# N32MC47x_DP47x register map
Vendor: Nsingtech Ltd.; File version: 1.0
Registers are 32-bit, read-write, reset 0x0 unless marked. A register's access mark holds for its fields unless they carry their own. Offsets are from the block's base; [hi:lo] are bit positions; {n}, {i} and the like mark numbered series; 'fields as' and 'values as' point back to an identical list.

## SHRTIM_Common — Super high resolution timer: Common functions
Base 0x40030380
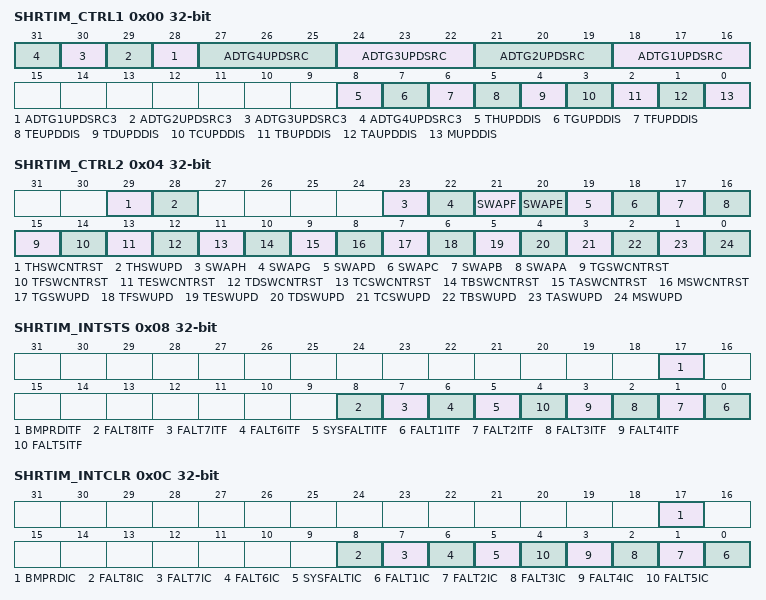
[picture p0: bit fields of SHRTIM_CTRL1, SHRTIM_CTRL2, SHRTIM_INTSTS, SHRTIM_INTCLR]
0x00 SHRTIM_CTRL1
  [n+27] ADTG{n}UPDSRC3 (n=1..4), [3n+15:3n+13] ADTG{n}UPDSRC (n=1..4), [8] THUPDDIS, [7] TGUPDDIS, [6] TFUPDDIS, [5] TEUPDDIS, [4] TDUPDDIS, [3] TCUPDDIS, [2] TBUPDDIS, [1] TAUPDDIS, [0] MUPDDIS
0x04 SHRTIM_CTRL2
  [29] THSWCNTRST, [28] THSWUPD, [23] SWAPH, [22] SWAPG, [21] SWAPF, [20] SWAPE, [19] SWAPD, [18] SWAPC, [17] SWAPB, [16] SWAPA, [15] TGSWCNTRST, [14] TFSWCNTRST, [13] TESWCNTRST, [12] TDSWCNTRST, [11] TCSWCNTRST, [10] TBSWCNTRST, [9] TASWCNTRST, [8] MSWCNTRST, [7] TGSWUPD, [6] TFSWUPD, [5] TESWUPD, [4] TDSWUPD, [3] TCSWUPD, [2] TBSWUPD, [1] TASWUPD, [0] MSWUPD
0x08 SHRTIM_INTSTS ro
  [17] BMPRDITF, [8] FALT8ITF, [7] FALT7ITF, [6] FALT6ITF, [5] SYSFALTITF, [n-1] FALT{n}ITF (n=1..5)
0x0C SHRTIM_INTCLR wo
  [17] BMPRDIC, [8] FALT8IC, [7] FALT7IC, [6] FALT6IC, [5] SYSFALTIC, [n-1] FALT{n}IC (n=1..5)
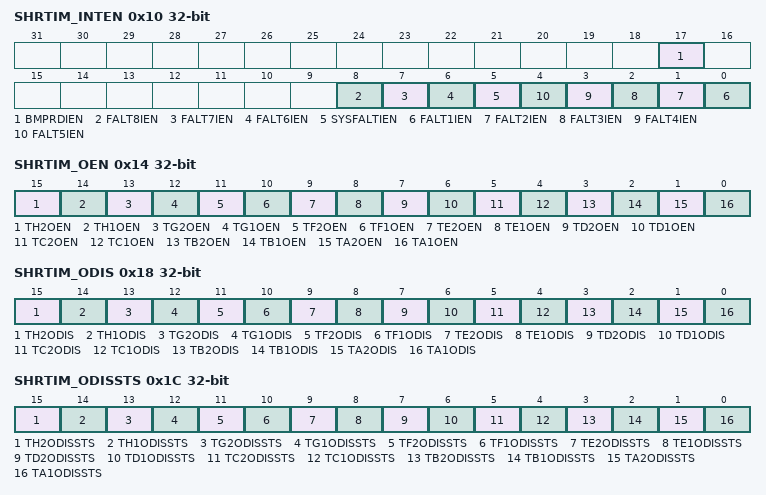
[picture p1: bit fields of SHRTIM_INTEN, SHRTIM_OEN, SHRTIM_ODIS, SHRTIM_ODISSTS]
0x10 SHRTIM_INTEN
  [17] BMPRDIEN, [8] FALT8IEN, [7] FALT7IEN, [6] FALT6IEN, [5] SYSFALTIEN, [n-1] FALT{n}IEN (n=1..5)
0x14 SHRTIM_OEN
  [15] TH2OEN, [14] TH1OEN, [13] TG2OEN, [12] TG1OEN, [11] TF2OEN, [10] TF1OEN, [9] TE2OEN, [8] TE1OEN, [7] TD2OEN, [6] TD1OEN, [5] TC2OEN, [4] TC1OEN, [3] TB2OEN, [2] TB1OEN, [1] TA2OEN, [0] TA1OEN
0x18 SHRTIM_ODIS wo
  [15] TH2ODIS, [14] TH1ODIS, [13] TG2ODIS, [12] TG1ODIS, [11] TF2ODIS, [10] TF1ODIS, [9] TE2ODIS, [8] TE1ODIS, [7] TD2ODIS, [6] TD1ODIS, [5] TC2ODIS, [4] TC1ODIS, [3] TB2ODIS, [2] TB1ODIS, [1] TA2ODIS, [0] TA1ODIS
0x1C SHRTIM_ODISSTS ro
  [15] TH2ODISSTS, [14] TH1ODISSTS, [13] TG2ODISSTS, [12] TG1ODISSTS, [11] TF2ODISSTS, [10] TF1ODISSTS, [9] TE2ODISSTS, [8] TE1ODISSTS, [7] TD2ODISSTS, [6] TD1ODISSTS, [5] TC2ODISSTS, [4] TC1ODISSTS, [3] TB2ODISSTS, [2] TB1ODISSTS, [1] TA2ODISSTS, [0] TA1ODISSTS
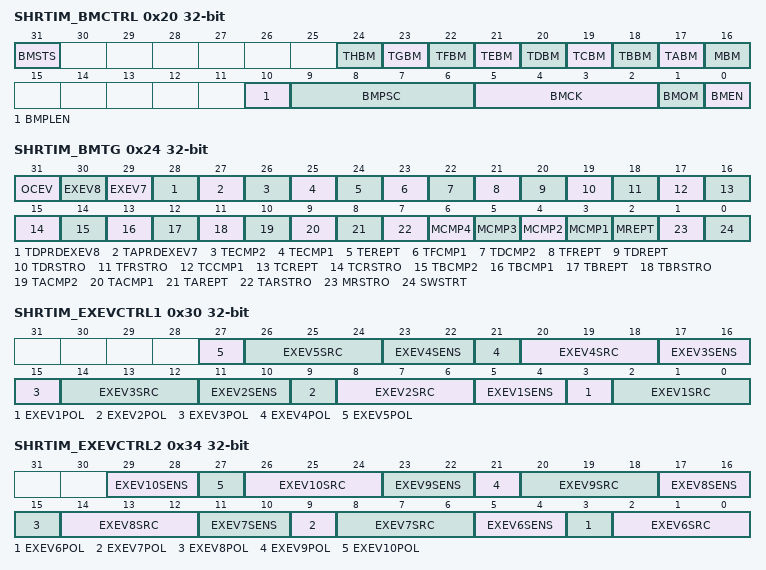
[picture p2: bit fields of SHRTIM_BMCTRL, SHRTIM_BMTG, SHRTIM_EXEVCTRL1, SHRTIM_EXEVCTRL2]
0x20 SHRTIM_BMCTRL
  [31] BMSTS, [24] THBM, [23] TGBM, [22] TFBM, [21] TEBM, [20] TDBM, [19] TCBM, [18] TBBM, [17] TABM, [16] MBM, [10] BMPLEN, [9:6] BMPSC, [5:2] BMCK, [1] BMOM, [0] BMEN
0x24 SHRTIM_BMTG
  [31] OCEV, [30] EXEV8, [29] EXEV7, [28] TDPRDEXEV8, [27] TAPRDEXEV7, [26] TECMP2, [25] TECMP1, [24] TEREPT, [23] TFCMP1, [22] TDCMP2, [21] TFREPT, [20] TDREPT, [19] TDRSTRO, [18] TFRSTRO, [17] TCCMP1, [16] TCREPT, [15] TCRSTRO, [14] TBCMP2, [13] TBCMP1, [12] TBREPT, [11] TBRSTRO, [10] TACMP2, [9] TACMP1, [8] TAREPT, [7] TARSTRO, [n+2] MCMP{n} (n=1..4), [2] MREPT, [1] MRSTRO, [0] SWSTRT
0x28 SHRTIM_BMCMP
0x2C SHRTIM_BMPRD
0x30 SHRTIM_EXEVCTRL1
  [6n-3] EXEV{n}POL (n=1..5), [6n-4:6n-6] EXEV{n}SRC (n=1..5), [6n-1:6n-2] EXEV{n}SENS (n=1..4)
0x34 SHRTIM_EXEVCTRL2
  [6n-31:6n-32] EXEV{n}SENS (n=6..10), [6n-33] EXEV{n}POL (n=6..10), [6n-34:6n-36] EXEV{n}SRC (n=6..10)
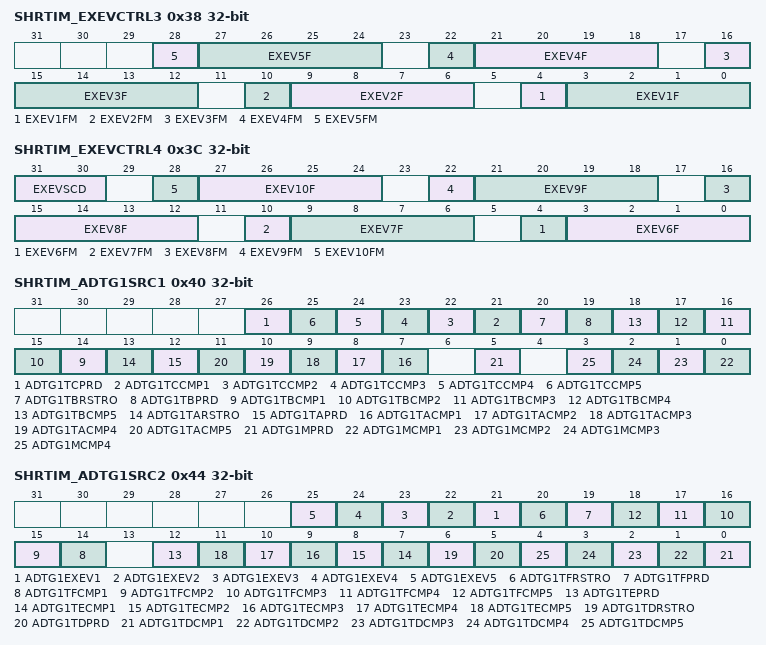
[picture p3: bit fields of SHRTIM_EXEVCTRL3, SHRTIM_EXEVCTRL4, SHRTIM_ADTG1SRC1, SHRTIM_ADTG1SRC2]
0x38 SHRTIM_EXEVCTRL3
  [6n-2] EXEV{n}FM (n=1..5), [6n-3:6n-6] EXEV{n}F (n=1..5)
0x3C SHRTIM_EXEVCTRL4
  [31:30] EXEVSCD, [6n-32] EXEV{n}FM (n=6..10), [6n-33:6n-36] EXEV{n}F (n=6..10)
0x40 SHRTIM_ADTG1SRC1
  [26] ADTG1TCPRD, [n+20] ADTG1TCCMP{n} (n=1..5), [20] ADTG1TBRSTRO, [19] ADTG1TBPRD, [n+13] ADTG1TBCMP{n} (n=1..5), [13] ADTG1TARSTRO, [12] ADTG1TAPRD, [n+6] ADTG1TACMP{n} (n=1..5), [5] ADTG1MPRD, [n-1] ADTG1MCMP{n} (n=1..4)
0x44 SHRTIM_ADTG1SRC2
  [n+20] ADTG1EXEV{n} (n=1..5), [20] ADTG1TFRSTRO, [19] ADTG1TFPRD, [n+13] ADTG1TFCMP{n} (n=1..5), [12] ADTG1TEPRD, [n+6] ADTG1TECMP{n} (n=1..5), [6] ADTG1TDRSTRO, [5] ADTG1TDPRD, [n-1] ADTG1TDCMP{n} (n=1..5)
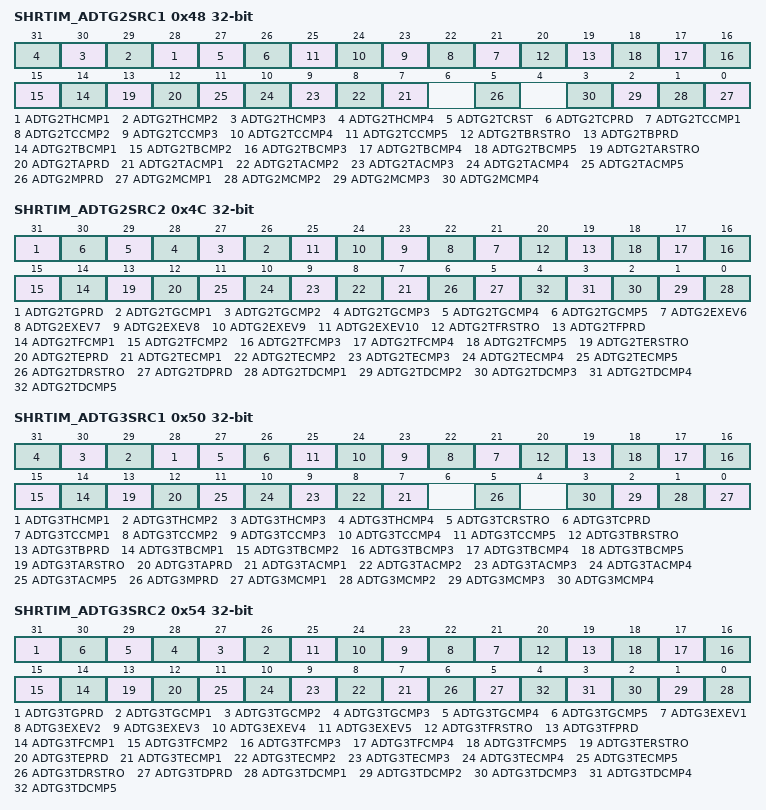
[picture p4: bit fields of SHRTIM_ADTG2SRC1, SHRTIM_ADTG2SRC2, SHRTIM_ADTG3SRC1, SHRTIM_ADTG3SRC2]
0x48 SHRTIM_ADTG2SRC1
  [n+27] ADTG2THCMP{n} (n=1..4), [27] ADTG2TCRST, [26] ADTG2TCPRD, [n+20] ADTG2TCCMP{n} (n=1..5), [20] ADTG2TBRSTRO, [19] ADTG2TBPRD, [n+13] ADTG2TBCMP{n} (n=1..5), [13] ADTG2TARSTRO, [12] ADTG2TAPRD, [n+6] ADTG2TACMP{n} (n=1..5), [5] ADTG2MPRD, [n-1] ADTG2MCMP{n} (n=1..4)
0x4C SHRTIM_ADTG2SRC2
  [31] ADTG2TGPRD, [n+25] ADTG2TGCMP{n} (n=1..5), [n+15] ADTG2EXEV{n} (n=6..10), [20] ADTG2TFRSTRO, [19] ADTG2TFPRD, [n+13] ADTG2TFCMP{n} (n=1..5), [13] ADTG2TERSTRO, [12] ADTG2TEPRD, [n+6] ADTG2TECMP{n} (n=1..5), [6] ADTG2TDRSTRO, [5] ADTG2TDPRD, [n-1] ADTG2TDCMP{n} (n=1..5)
0x50 SHRTIM_ADTG3SRC1
  [n+27] ADTG3THCMP{n} (n=1..4), [27] ADTG3TCRSTRO, [26] ADTG3TCPRD, [n+20] ADTG3TCCMP{n} (n=1..5), [20] ADTG3TBRSTRO, [19] ADTG3TBPRD, [n+13] ADTG3TBCMP{n} (n=1..5), [13] ADTG3TARSTRO, [12] ADTG3TAPRD, [n+6] ADTG3TACMP{n} (n=1..5), [5] ADTG3MPRD, [n-1] ADTG3MCMP{n} (n=1..4)
0x54 SHRTIM_ADTG3SRC2
  [31] ADTG3TGPRD, [n+25] ADTG3TGCMP{n} (n=1..5), [n+20] ADTG3EXEV{n} (n=1..5), [20] ADTG3TFRSTRO, [19] ADTG3TFPRD, [n+13] ADTG3TFCMP{n} (n=1..5), [13] ADTG3TERSTRO, [12] ADTG3TEPRD, [n+6] ADTG3TECMP{n} (n=1..5), [6] ADTG3TDRSTRO, [5] ADTG3TDPRD, [n-1] ADTG3TDCMP{n} (n=1..5)
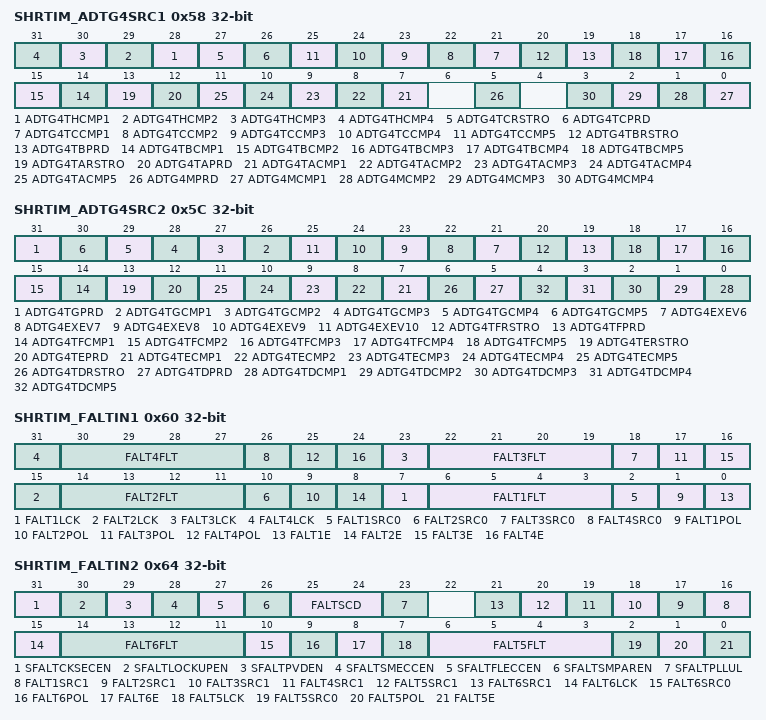
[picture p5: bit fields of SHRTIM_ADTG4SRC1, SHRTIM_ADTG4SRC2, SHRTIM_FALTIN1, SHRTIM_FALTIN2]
0x58 SHRTIM_ADTG4SRC1
  [n+27] ADTG4THCMP{n} (n=1..4), [27] ADTG4TCRSTRO, [26] ADTG4TCPRD, [n+20] ADTG4TCCMP{n} (n=1..5), [20] ADTG4TBRSTRO, [19] ADTG4TBPRD, [n+13] ADTG4TBCMP{n} (n=1..5), [13] ADTG4TARSTRO, [12] ADTG4TAPRD, [n+6] ADTG4TACMP{n} (n=1..5), [5] ADTG4MPRD, [n-1] ADTG4MCMP{n} (n=1..4)
0x5C SHRTIM_ADTG4SRC2
  [31] ADTG4TGPRD, [n+25] ADTG4TGCMP{n} (n=1..5), [n+15] ADTG4EXEV{n} (n=6..10), [20] ADTG4TFRSTRO, [19] ADTG4TFPRD, [n+13] ADTG4TFCMP{n} (n=1..5), [13] ADTG4TERSTRO, [12] ADTG4TEPRD, [n+6] ADTG4TECMP{n} (n=1..5), [6] ADTG4TDRSTRO, [5] ADTG4TDPRD, [n-1] ADTG4TDCMP{n} (n=1..5)
0x60 SHRTIM_FALTIN1
  [8n-1] FALT{n}LCK (n=1..4), [8n-2:8n-5] FALT{n}FLT (n=1..4), [8n-6] FALT{n}SRC0 (n=1..4), [8n-7] FALT{n}POL (n=1..4), [8n-8] FALT{n}E (n=1..4)
0x64 SHRTIM_FALTIN2
  [31] SFALTCKSECEN, [30] SFALTLOCKUPEN, [29] SFALTPVDEN, [28] SFALTSMECCEN, [27] SFALTFLECCEN, [26] SFALTSMPAREN, [25:24] FALTSCD, [23] SFALTPLLUL, [n+15] FALT{n}SRC1 (n=1..6), [15] FALT6LCK, [14:11] FALT6FLT, [10] FALT6SRC0, [9] FALT6POL, [8] FALT6E, [7] FALT5LCK, [6:3] FALT5FLT, [2] FALT5SRC0, [1] FALT5POL, [0] FALT5E
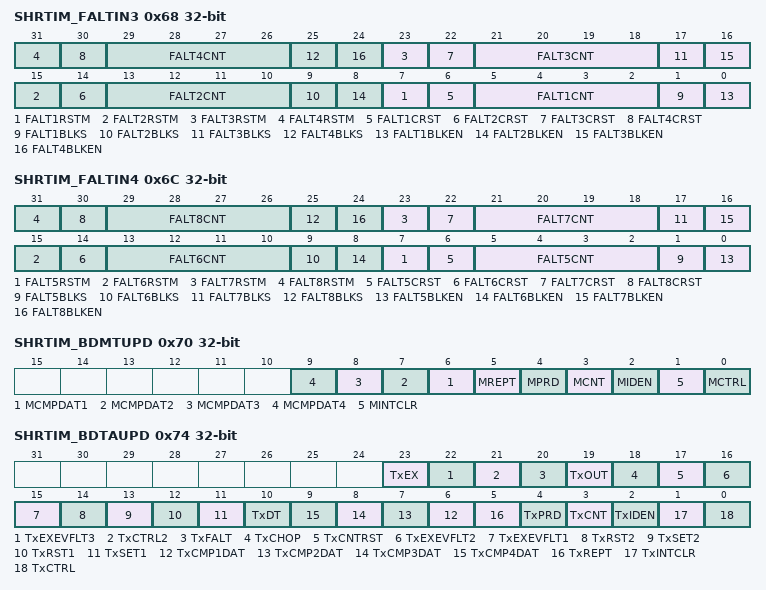
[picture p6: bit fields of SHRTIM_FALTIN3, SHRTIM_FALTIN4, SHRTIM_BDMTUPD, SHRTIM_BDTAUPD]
0x68 SHRTIM_FALTIN3
  [8n-1] FALT{n}RSTM (n=1..4), [8n-2] FALT{n}CRST (n=1..4), [8n-3:8n-6] FALT{n}CNT (n=1..4), [8n-7] FALT{n}BLKS (n=1..4), [8n-8] FALT{n}BLKEN (n=1..4)
0x6C SHRTIM_FALTIN4
  [8n-33] FALT{n}RSTM (n=5..8), [8n-34] FALT{n}CRST (n=5..8), [8n-35:8n-38] FALT{n}CNT (n=5..8), [8n-39] FALT{n}BLKS (n=5..8), [8n-40] FALT{n}BLKEN (n=5..8)
0x70 SHRTIM_BDMTUPD
  [n+5] MCMPDAT{n} (n=1..4), [5] MREPT, [4] MPRD, [3] MCNT, [2] MIDEN, [1] MINTCLR, [0] MCTRL
0x74 SHRTIM_BDTAUPD
  [23] TxEX, [22] TxEXEVFLT3, [21] TxCTRL2, [20] TxFALT, [19] TxOUT, [18] TxCHOP, [17] TxCNTRST, [16] TxEXEVFLT2, [15] TxEXEVFLT1, [14] TxRST2, [13] TxSET2, [12] TxRST1, [11] TxSET1, [10] TxDT, [n+5] TxCMP{n}DAT (n=1..4), [5] TxREPT, [4] TxPRD, [3] TxCNT, [2] TxIDEN, [1] TxINTCLR, [0] TxCTRL
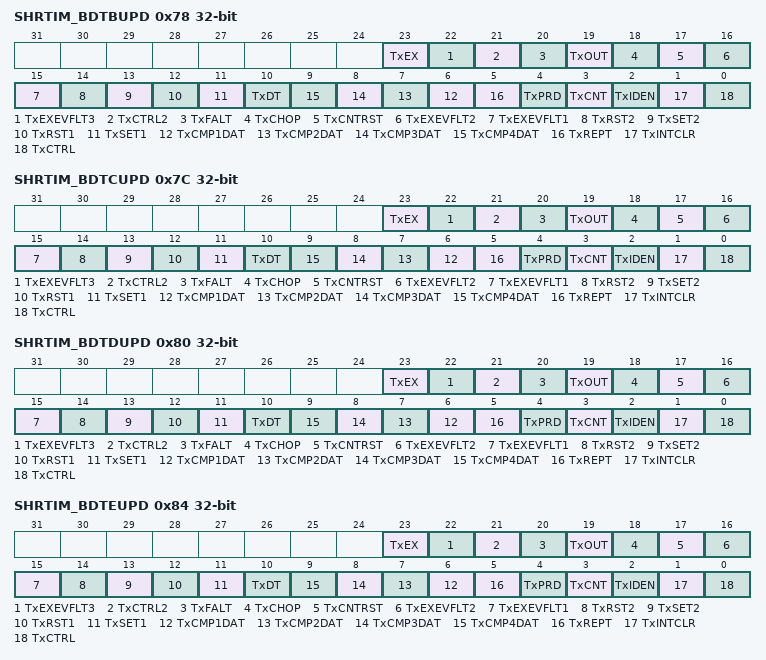
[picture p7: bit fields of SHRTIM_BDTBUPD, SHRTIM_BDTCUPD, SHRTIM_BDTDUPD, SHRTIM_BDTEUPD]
0x78 SHRTIM_BDTBUPD
  fields as SHRTIM_BDTAUPD
0x7C SHRTIM_BDTCUPD
  fields as SHRTIM_BDTAUPD
0x80 SHRTIM_BDTDUPD
  fields as SHRTIM_BDTAUPD
0x84 SHRTIM_BDTEUPD
  fields as SHRTIM_BDTAUPD
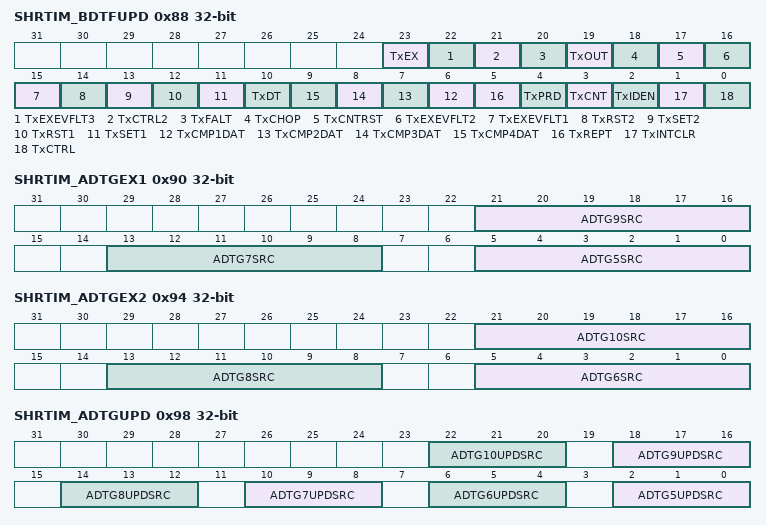
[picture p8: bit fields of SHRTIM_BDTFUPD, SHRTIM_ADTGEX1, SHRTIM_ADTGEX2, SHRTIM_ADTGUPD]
0x88 SHRTIM_BDTFUPD
  fields as SHRTIM_BDTAUPD
0x8C SHRTIM_BDDAT wo
  [31:0] BDMADATA
0x90 SHRTIM_ADTGEX1
  [21:16] ADTG9SRC, [13:8] ADTG7SRC, [5:0] ADTG5SRC
0x94 SHRTIM_ADTGEX2
  [21:16] ADTG10SRC, [13:8] ADTG8SRC, [5:0] ADTG6SRC
0x98 SHRTIM_ADTGUPD
  [4n-18:4n-20] ADTG{n}UPDSRC (n=5..10)
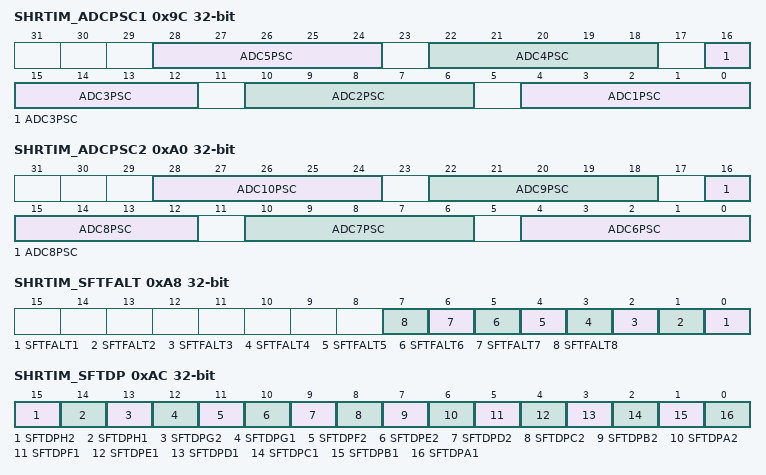
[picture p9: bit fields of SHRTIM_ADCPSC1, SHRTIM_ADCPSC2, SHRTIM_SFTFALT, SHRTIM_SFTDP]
0x9C SHRTIM_ADCPSC1
  [6n-2:6n-6] ADC{n}PSC (n=1..5)
0xA0 SHRTIM_ADCPSC2
  [6n-32:6n-36] ADC{n}PSC (n=6..10)
0xA8 SHRTIM_SFTFALT
  [n-1] SFTFALT{n} (n=1..8)
0xAC SHRTIM_SFTDP
  [15] SFTDPH2, [14] SFTDPH1, [13] SFTDPG2, [12] SFTDPG1, [11] SFTDPF2, [10] SFTDPE2, [9] SFTDPD2, [8] SFTDPC2, [7] SFTDPB2, [6] SFTDPA2, [5] SFTDPF1, [4] SFTDPE1, [3] SFTDPD1, [2] SFTDPC1, [1] SFTDPB1, [0] SFTDPA1
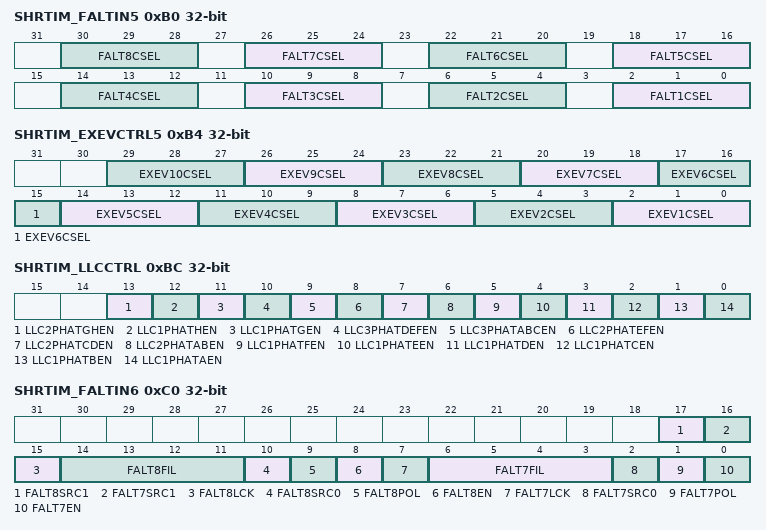
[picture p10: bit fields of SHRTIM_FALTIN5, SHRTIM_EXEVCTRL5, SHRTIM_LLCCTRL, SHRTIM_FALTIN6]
0xB0 SHRTIM_FALTIN5
  [4n-2:4n-4] FALT{n}CSEL (n=1..8)
0xB4 SHRTIM_EXEVCTRL5
  [3n-1:3n-3] EXEV{n}CSEL (n=1..10)
0xBC SHRTIM_LLCCTRL
  [13] LLC2PHATGHEN, [12] LLC1PHATHEN, [11] LLC1PHATGEN, [10] LLC3PHATDEFEN, [9] LLC3PHATABCEN, [8] LLC2PHATEFEN, [7] LLC2PHATCDEN, [6] LLC2PHATABEN, [5] LLC1PHATFEN, [4] LLC1PHATEEN, [3] LLC1PHATDEN, [2] LLC1PHATCEN, [1] LLC1PHATBEN, [0] LLC1PHATAEN
0xC0 SHRTIM_FALTIN6
  [17] FALT8SRC1, [16] FALT7SRC1, [15] FALT8LCK, [14:11] FALT8FIL, [10] FALT8SRC0, [9] FALT8POL, [8] FALT8EN, [7] FALT7LCK, [6:3] FALT7FIL, [2] FALT7SRC0, [1] FALT7POL, [0] FALT7EN
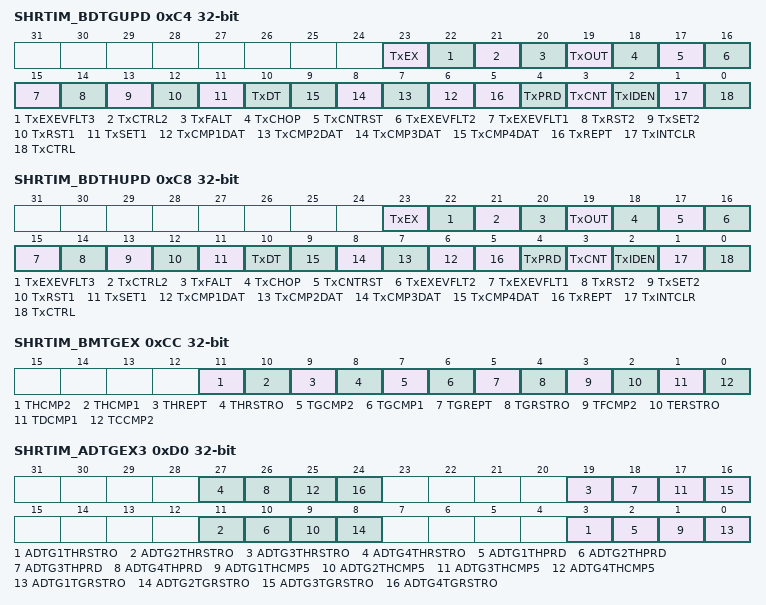
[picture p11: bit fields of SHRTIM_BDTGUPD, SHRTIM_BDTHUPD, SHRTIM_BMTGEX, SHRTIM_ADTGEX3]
0xC4 SHRTIM_BDTGUPD
  fields as SHRTIM_BDTAUPD
0xC8 SHRTIM_BDTHUPD
  fields as SHRTIM_BDTAUPD
0xCC SHRTIM_BMTGEX
  [11] THCMP2, [10] THCMP1, [9] THREPT, [8] THRSTRO, [7] TGCMP2, [6] TGCMP1, [5] TGREPT, [4] TGRSTRO, [3] TFCMP2, [2] TERSTRO, [1] TDCMP1, [0] TCCMP2
0xD0 SHRTIM_ADTGEX3
  [8n-5] ADTG{n}THRSTRO (n=1..4), [8n-6] ADTG{n}THPRD (n=1..4), [8n-7] ADTG{n}THCMP5 (n=1..4), [8n-8] ADTG{n}TGRSTRO (n=1..4)
